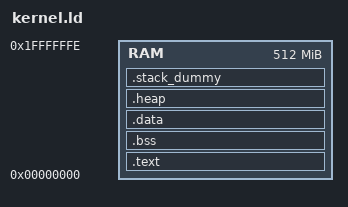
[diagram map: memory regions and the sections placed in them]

/* 512MB RAM on my Raspberry Pi */
MEMORY
{
	RAM : ORIGIN = 0X00000000, LENGTH = 0x1fffffff
}

SECTIONS 
{

/*
	.init 0x0000 : 
	{
		*(.init)
	} > RAM
	
	.text : 
	{
		*(.text)
	} > RAM
*/

	.text :
	{
		KEEP(*(.evt))
		*(.text*)

		KEEP(*(.init))
		KEEP(*(.fini))

		/* .ctors */
		*crtbegin.o(.ctors)
		*crtbegin?.o(.ctors)
		*(EXCLUDE_FILE(*crtend?.o *crtend.o) .ctors)
		*(SORT(.ctors.*))
		*(.ctors)

		/* .dtors */
 		*crtbegin.o(.dtors)
 		*crtbegin?.o(.dtors)
 		*(EXCLUDE_FILE(*crtend?.o *crtend.o) .dtors)
 		*(SORT(.dtors.*))
 		*(.dtors)

		*(.rodata*)

		KEEP(*(.eh_frame*))
	} > RAM
	
	.bss :
	{
		. = ALIGN(4);
		__bss_start__ = .;
		*(.bss*)
		*(COMMON)
		. = ALIGN(4);
		__bss_end__ = .;
	} > RAM
	
	.data : 
	{
		*(.data)
	} > RAM

	/DISCARD/ : {
		*(*)
	} 
	
	.heap (COPY):
	{
		__end__ = .;
		PROVIDE(end = .);
		*(.heap*)
		__HeapLimit = .;
	} > RAM
	
	/* .stack_dummy section doesn't contains any symbols. It is only
	 * used for linker to calculate size of stack sections, and assign
	 * values to stack symbols later */
	.stack_dummy (COPY):
	{
		*(.stack*)
	} > RAM

	/* Set stack top to end of RAM, and stack limit move down by
	 * size of stack_dummy section */
	__StackTop = ORIGIN(RAM) + LENGTH(RAM);
	__StackLimit = __StackTop - SIZEOF(.stack_dummy);
	PROVIDE(__stack = __StackTop);
	
	/* Check if data + heap + stack exceeds RAM limit */
	ASSERT(__StackLimit >= __HeapLimit, "region RAM overflowed with stack")
}

